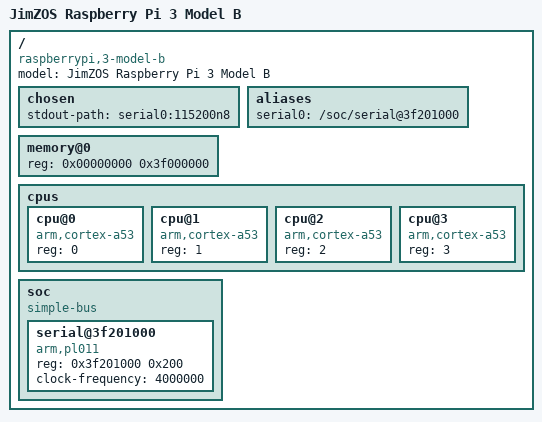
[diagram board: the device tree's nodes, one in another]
/dts-v1/;

/*
 * jimzos.dts — minimal device tree for JimZOS on the Raspberry Pi 3 (BCM2837),
 * as emulated by `qemu-system-aarch64 -M raspi3b`.
 *
 * This is deliberately a small tree describing what the kernel needs to
 * bootstrap: the CPUs, the system RAM, and the PL011 UART console (chosen via
 * /chosen stdout-path). More peripherals (interrupt controller, timer, ...)
 * get added as the kernel grows a device model.
 *
 * Build:  dtc -I dts -O dtb -o jimzos.dtb jimzos.dts   (or `zig build dtb`)
 */

/ {
	#address-cells = <1>;	/* addresses are a single 32-bit cell ... */
	#size-cells = <1>;	/* ... and so are region sizes (Pi3 RAM < 4 GiB) */

	model = "JimZOS Raspberry Pi 3 Model B";
	compatible = "raspberrypi,3-model-b", "brcm,bcm2837";

	/*
	 * Boot console. stdout-path names it: the part before ':' is an /aliases
	 * key (serial0), the rest ("115200n8" = baud/parity/bits) is a hint the
	 * kernel may honour. The kernel resolves serial0 -> /soc/serial@3f201000
	 * and configures that PL011.
	 */
	chosen {
		stdout-path = "serial0:115200n8";
	};

	aliases {
		serial0 = "/soc/serial@3f201000";
	};

	/*
	 * System RAM. The BCM2837 places the peripheral (MMIO) window at
	 * 0x3f00_0000, so usable RAM for the ARM cores runs 0x0 .. 0x3eff_ffff
	 * (1008 MiB). This matches RAM_TOP / MMIO_BASE in boot1_phys.zig.
	 */
	memory@0 {
		device_type = "memory";
		reg = <0x00000000 0x3f000000>;
	};

	/*
	 * The four Cortex-A53 cores. `reg` is the core's MPIDR_EL1.Aff0 value,
	 * which boot0_entry.S masks out to park the secondaries (the
	 * `and x7, x7, #3` there). SMP bring-up details (enable-method /
	 * cpu-release-addr or PSCI) are intentionally omitted until we
	 * actually start the secondary cores.
	 */
	cpus {
		#address-cells = <1>;
		#size-cells = <0>;

		cpu@0 {
			device_type = "cpu";
			compatible = "arm,cortex-a53";
			reg = <0>;
		};

		cpu@1 {
			device_type = "cpu";
			compatible = "arm,cortex-a53";
			reg = <1>;
		};

		cpu@2 {
			device_type = "cpu";
			compatible = "arm,cortex-a53";
			reg = <2>;
		};

		cpu@3 {
			device_type = "cpu";
			compatible = "arm,cortex-a53";
			reg = <3>;
		};
	};

	/*
	 * On-chip peripherals. Real Pi device trees give this a translating
	 * `ranges` from legacy 0x7e00_0000 VideoCore bus addresses to the
	 * 0x3f00_0000 ARM-physical window. We keep it simple with an identity
	 * `ranges` (and physical addresses), so a node's `reg` IS the MMIO
	 * address — the DeviceTree lib does not translate ranges for us.
	 */
	soc {
		compatible = "simple-bus";
		#address-cells = <1>;
		#size-cells = <1>;
		ranges;

		/*
		 * PL011 (PrimeCell) UART0. The generic driver consumes reg and
		 * clock-frequency; the raspi3 platform hook supplies the VideoCore
		 * clock and GPIO setup before the early console configures PL011.
		 */
		serial@3f201000 {
			compatible = "arm,pl011", "arm,primecell";
			reg = <0x3f201000 0x200>;
			clock-frequency = <4000000>;
			status = "okay";
		};
	};
};
